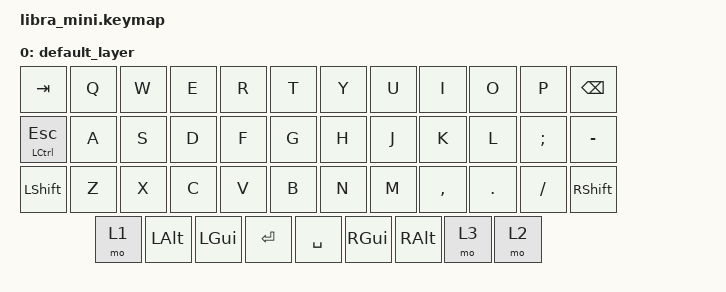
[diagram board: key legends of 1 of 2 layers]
/*
 * Copyright (c) 2021 Nick Winans
 *
 * SPDX-License-Identifier: MIT
 */

#include <behaviors.dtsi>
#include <dt-bindings/zmk/keys.h>
#include <dt-bindings/zmk/bt.h>

/ {
	keymap {
		compatible = "zmk,keymap";

		default_layer {
			bindings = <
          &kp TAB  &kp Q  &kp W  &kp E  &kp R  &kp T            &kp Y  &kp U  &kp I  &kp O  &kp P  &kp BSPC
          &mt LCTL ESC  &kp A  &kp S  &kp D  &kp F  &kp G       &kp H  &kp J  &kp K  &kp L  &kp SEMI &kp MINUS
          &kp LSHFT   &kp Z  &kp X  &kp C  &kp V  &kp B         &kp N  &kp M  &kp COMMA &kp DOT &kp FSLH &kp RSHFT
          &mo 1 &kp LALT &kp LGUI             &kp ENTER         &kp SPACE &kp RGUI  &kp RALT    &mo 3   &mo 2
			>;
		};

		layer_1 {
			bindings = <
          &trans  &trans  &trans  &trans  &trans  &trans            &trans  &trans  &trans  &trans  &kp LBKT &kp GRAVE
          &trans  &kp BSLH  &kp PIPE  &trans  &trans  &trans        &trans  &kp N4  &kp N5  &kp N6  &kp RBKT  &kp SQT
          &trans   &trans  &trans  &trans  &trans  &trans           &kp N0  &kp N1  &kp N2 &kp N3 &kp POUND &trans
          &trans &trans &trans             &trans                   &trans  &trans    &trans   &bootloader
			>;
		};
	};
};
